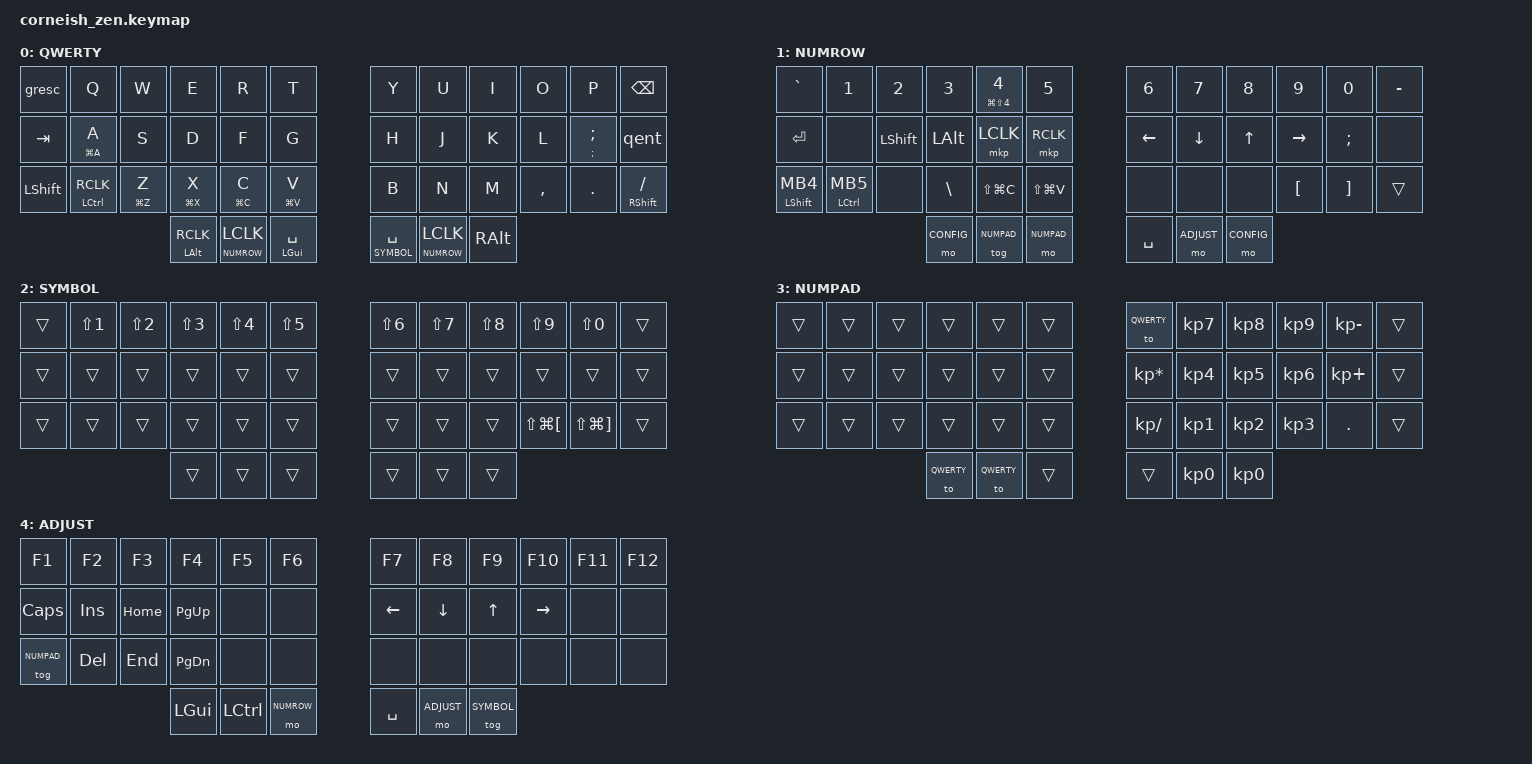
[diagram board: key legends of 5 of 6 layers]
/*
*
* Copyright (c) 2021 lowprokb.ca
* SPDX-License-Identifier: MIT
*
*   [KJH] = COMBO(kjh_combo, LALT(KC_LEFT)),
*   [KLK] = COMBO(klk_combo, LALT(KC_RIGHT)),
*   [KCJKL] = COMBO(kcjkl_combo, LCTL(KC_E)),
*   [KCHJK] = COMBO(kchjk_combo, LCTL(KC_A)),
*
*/

#include <behaviors.dtsi>
#include <dt-bindings/zmk/keys.h>
#include <dt-bindings/zmk/bt.h>
#include <dt-bindings/zmk/mouse.h>
#include <dt-bindings/zmk/outputs.h>

#define QWERTY 0
#define NUMROW 1
#define SYMBOL 2
#define NUMPAD 3
#define ADJUST 4
#define CONFIG 5

/ {
    combos {
        compatible = "zmk,combos";
        combo_hj {
            timeout-ms = <50>;
            key-positions = <18 19>;
            bindings = <&kp LA(LEFT)>;
        };
        combo_kl {
            timeout-ms = <50>;
            key-positions = <20 21>;
            bindings = <&kp LA(RIGHT)>;
        };
        combo_hjk {
            timeout-ms = <50>;
            key-positions = <18 19 20>;
            bindings = <&kp LC(A)>;
        };
        combo_jkl {
            timeout-ms = <50>;
            key-positions = <19 20 21>;
            bindings = <&kp LC(E)>;
        };
        combo_lowerar {
            timeout-ms = <40>;
            key-positions = <4 13>;
            layers = <NUMROW>;
            bindings = <&my_zero_param_macro>;
        };
        combo_89 {
            timeout-ms = <50>;
            key-positions = <8 9>;
            layers = <NUMROW>;
            bindings = <&kp LS(N9)>;
        };
        combo_90 {
            timeout-ms = <50>;
            key-positions = <9 10>;
            layers = <NUMROW>;
            bindings = <&kp LS(N0)>;
        };
        combo_9bs {
            timeout-ms = <50>;
            key-positions = <10 11>;
            bindings = <&kp EQUAL>;
        };
        combo_bsent {
            timeout-ms = <50>;
            key-positions = <11 23>;
            bindings = <&kp BSLH>;
        };
        combo_df {
            timeout-ms = <50>;
            key-positions = <15 16>;
            bindings = <&kp LG(F)>;
        };
        combo_sdf {
            timeout-ms = <50>;
            key-positions = <14 15 16>;
            bindings = <&kp LA(LS(LG(F)))>;
        };
        combo_bn {
            timeout-ms = <50>;
            key-positions = <30 31>;
            bindings = <&kp N>;
        };
        combo_nm {
            timeout-ms = <50>;
            key-positions = <31 32>;
            bindings = <&kp M>;
        };
        combo_mcomma {
            timeout-ms = <50>;
            key-positions = <32 33>;
            bindings = <&kp M>;
        };
        combo_mperiod {
            timeout-ms = <50>;
            key-positions = <32 34>;
            bindings = <&kp C_MUTE>;
        };
    };
    macros {
        ZMK_MACRO(my_zero_param_macro,
          wait-ms = <10>;
          tap-ms = <20>;
          bindings = <&kp W ENTER>;
        )
    };
    behaviors {
        mt_: custom_mod_tap {
            compatible = "zmk,behavior-hold-tap";
            label = "MOD_TAP";
            #binding-cells = <2>;
            flavor = "tap-preferred";
            tapping-term-ms = <300>;
            quick_tap_ms = <500>;
            bindings = <&kp>, <&kp>;
        };
        mt_mp_: custom_mod_tap_mp {
            compatible = "zmk,behavior-hold-tap";
            label = "MOD_TAP_MP";
            #binding-cells = <2>;
            flavor = "hold-preferred";
            tapping-term-ms = <150>;
            quick_tap_ms = <125>;
            bindings = <&kp>, <&mkp>;
        };
        mtgui_: custom_mod_tap_gui {
            compatible = "zmk,behavior-hold-tap";
            label = "MOD_TAP_HOLD_GUI";
            #binding-cells = <2>;
            flavor = "hold-preferred";
            tapping-term-ms = <100>;
            quick_tap_ms = <200>;
            bindings = <&kp>, <&kp>;
        };
        lt_: custom_layer_tap {
            compatible = "zmk,behavior-hold-tap";
            label = "LAYER_TAP";
            #binding-cells = <2>;
            flavor = "balanced";
            tapping-term-ms = <500>;
            quick_tap_ms = <200>;
            bindings = <&mo>, <&kp>;
        };
        mp_int_: custom_layer_tap_mp_int {
            compatible = "zmk,behavior-hold-tap";
            label = "LAYER_TAP_MP_int";
            #binding-cells = <2>;
            flavor = "hold-preferred";
            tapping-term-ms = <0>;
            quick_tap_ms = <200>;
            bindings = <&mkp>, <&mo>; 
        };
        lm: lm {
            compatible = "zmk,behavior-macro-two-param";
            wait-ms = <0>;
            tap-ms = <0>;
            #binding-cells = <2>;
            bindings
                = <&macro_param_1to1>
                , <&macro_press &mo MACRO_PLACEHOLDER>
                , <&macro_param_2to1>
                , <&macro_press &mkp MACRO_PLACEHOLDER>
                , <&macro_pause_for_release>
                , <&macro_param_2to1>
                , <&macro_release &mkp MACRO_PLACEHOLDER>
                , <&macro_param_1to1>
                , <&macro_release &mo MACRO_PLACEHOLDER>
                ;
        };
        lmzero: lmzero {
            compatible = "zmk,behavior-macro";
            wait-ms = <0>;
            tap-ms = <0>;
            #binding-cells = <0>;
            bindings
                = <&macro_press &mo NUMROW>
                , <&macro_press &kp F24>
                , <&macro_pause_for_release>
                , <&macro_release &kp F24>
                , <&macro_release &mo NUMROW>
                ;
        };
        lt_mp_: custom_layer_tap_mp {
            compatible = "zmk,behavior-hold-tap";
            label = "LAYER_TAP_MP";
            #binding-cells = <2>;
            flavor = "hold-preferred";
            tapping-term-ms = <150>;
            quick_tap_ms = <300>;
            bindings = <&lmzero>, <&mkp>;
        };
        td_lclk_layer_ldrag: tap_dance_mod_tap {
            compatible = "zmk,behavior-tap-dance";
            #binding-cells = <0>;
            tapping-term-ms = <150>;
            bindings = <&lt_mp_ NUMROW LCLK>, <&mkp LCLK>;
        };
        gresc: grave_escape {
            compatible = "zmk,behavior-mod-morph";
            label = "GRAVE_ESCAPE";
            #binding-cells = <0>;
            bindings = <&kp ESC>, <&kp GRAVE>;
            mods = <(MOD_LGUI|MOD_LSFT|MOD_RGUI|MOD_RSFT)>;
            keep-mods = <(MOD_LGUI)>;
        };
        qent: quote_enter {
            compatible = "zmk,behavior-mod-morph";
            label = "QUOTE_ENTER";
            #binding-cells = <0>;
            bindings = <&kp ENTER>, <&kp APOS>;
            mods = <(MOD_LSFT)>;
        };
        shtqcolon: quote_colon {
            compatible = "zmk,behavior-mod-morph";
            label = "QUOTE_COLON";
            #binding-cells = <0>;
            bindings = <&kp APOS>, <&kp SEMI>;
            mods = <(MOD_LSFT|MOD_RSFT)>;
        };
        ht: holdtap {
            compatible = "zmk,behavior-hold-tap";
            label = "HOLDTAP";
            #binding-cells = <2>;
            tapping-term-ms = <300>;
            quick_tap_ms = <0>;
            flavor = "tap-preferred";
            bindings = <&kp>, <&kp>;
        };
        htreset: holdtapreset {
            compatible = "zmk,behavior-hold-tap";
            label = "HOLDTAPRESET";
            #binding-cells = <2>;
            tapping-term-ms = <300>;
            quick_tap_ms = <0>;
            flavor = "tap-preferred";
            bindings = <&sys_reset>, <&kp>;
        };
        htbootloader: htbootloader {
            compatible = "zmk,behavior-hold-tap";
            label = "HTBOOTLOADER";
            #binding-cells = <2>;
            tapping-term-ms = <300>;
            quick_tap_ms = <0>;
            flavor = "tap-preferred";
            bindings = <&bootloader>, <&kp>;
        };
        htpw: htpw {
            compatible = "zmk,behavior-hold-tap";
            label = "HTPW";
            #binding-cells = <2>;
            tapping-term-ms = <300>;
            quick_tap_ms = <0>;
            flavor = "tap-preferred";
            bindings = <&my_zero_param_macro>, <&kp>;
        };
        htsemi: hotldtapsemi {
            compatible = "zmk,behavior-hold-tap";
            label = "HOLDTAPSEMI";
            #binding-cells = <2>;
            tapping-term-ms = <300>;
            quick_tap_ms = <0>;
            flavor = "tap-preferred";
            bindings = <&kp>, <&shtqcolon>;
        };
    };

        keymap {
                compatible = "zmk,keymap";

                default_layer {
                        label = "QWERTY";
                        bindings = <
   &gresc   &kp Q &kp W &kp E &kp R &kp T      &kp Y &kp U &kp I    &kp O   &kp P    &kp BKSP
   &kp TAB  &ht LG(A) A &kp S &kp D &kp F &kp G      &kp H &kp J &kp K    &kp L   &htsemi SEMI SEMI &qent
   &kp LSHFT &mt_mp_ LCTL RCLK &ht LG(Z) Z  &ht LG(X) X  &ht LG(C) C &ht LG(V) V   &kp B &kp N &kp M &kp CMMA &kp DOT &mt RSHIFT FSLH
                &mt_mp_ LALT RCLK &lt_mp_ NUMROW LCLK &mtgui_ LGUI SPC     &lt_ SYMBOL SPC &lt_mp_ NUMROW LCLK &kp RALT
                        >;
                };

                numrow_layer {
                        label = "NUMROW";
                        bindings = <
   &kp GRAVE         &kp N1           &kp N2     &kp N3    &ht LG(LS(N4)) N4  &kp N5            &kp N6   &kp N7   &kp N8 &kp N9    &kp N0   &kp MINUS
   &kp ENTER         &none            &kp LSHFT  &kp LALT  &mkp LCLK          &mkp RCLK         &kp LEFT &kp DOWN &kp UP &kp RIGHT &kp SEMI &none
   &mt_mp_ LSHFT MB4 &mt_mp_ LCTL MB5 &none      &kp BSLH  &kp LS(LG(C))      &kp LS(LG(V))     &none    &none    &none  &kp LBKT  &kp RBKT    &trans
                                                       &mo CONFIG &tog NUMPAD &mo NUMPAD        &kp SPC &mo ADJUST &mo CONFIG
                        >;
                };

                symbol {
                        label = "SYMBOL";
                        bindings = <
   &trans &kp LS(N1) &kp LS(N2) &kp LS(N3) &kp LS(N4) &kp LS(N5)    &kp LS(N6) &kp LS(N7) &kp LS(N8) &kp LS(N9) &kp LS(N0) &trans
   &trans &trans &trans &trans &trans &trans    &trans &trans &trans &trans &trans &trans
   &trans &trans &trans &trans &trans &trans    &trans &trans &trans &kp LS(LG(LBKT)) &kp LS(LG(RBKT)) &trans
               &trans &trans &trans    &trans &trans &trans
                        >;
                };

                numpad_layer {
                        label = "NUMPAD";
                        bindings = <
   &trans &trans &trans &trans &trans &trans    &to QWERTY    &kp KP_N7 &kp KP_N8 &kp KP_N9 &kp KP_MINUS &trans
   &trans &trans &trans &trans &trans &trans    &kp KP_ASTERISK &kp KP_N4 &kp KP_N5 &kp KP_N6 &kp KP_PLUS  &trans
   &trans &trans &trans &trans &trans &trans    &kp KP_SLASH    &kp KP_N1 &kp KP_N2 &kp KP_N3 &kp DOT &trans
                        &to QWERTY &to QWERTY &trans    &trans &kp KP_N0 &kp KP_N0
                        >;
                };

                adjust_layer {
                        label = "ADJUST";
                        bindings = <
   &kp F1      &kp F2  &kp F3   &kp F4    &kp F5 &kp F6    &kp F7   &kp F8   &kp F9 &kp F10   &kp F11 &kp F12
   &kp CAPS    &kp INS &kp HOME &kp PG_UP &none  &none     &kp LEFT &kp DOWN &kp UP &kp RIGHT &none   &none
   &tog NUMPAD &kp DEL &kp END  &kp PG_DN &none  &none     &none    &none    &none  &none     &none   &none
                           &kp LGUI &kp LCTL &mo NUMROW    &kp SPC &mo ADJUST &tog SYMBOL
                        >;
                };

                config_layer {
                        label = "CONFIG";
                        bindings = <
   &htreset &none &none   &none  &none  &none        &none        &htbootloader &none &none           &htbootloader &none &none   &htreset &none &none  &none &none &none &htpw &none &none
   &bt BT_CLR &bt BT_SEL 0 &bt BT_SEL 1 &bt BT_SEL 2 &bt BT_SEL 3 &bt BT_SEL 4    &none &none &none &none &none &none
   &htpw &none &none      &none        &none        &none        &none        &none           &none &none &none &none &none &none
                                                &to QWERTY &to QWERTY &to QWERTY    &to QWERTY &to QWERTY &to QWERTY
                        >;
                };
        };
};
